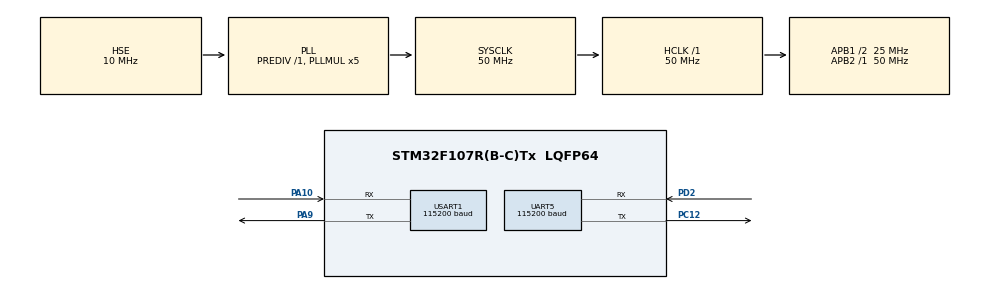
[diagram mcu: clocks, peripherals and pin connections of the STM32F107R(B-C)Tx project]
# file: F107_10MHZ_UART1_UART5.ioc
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Mcu.Family=STM32F1
Mcu.Name=STM32F107R(B-C)Tx
Mcu.Package=LQFP64
NVIC.PriorityGroup=NVIC_PRIORITYGROUP_4
NVIC.TIM1_UP_IRQn=true\:15\:0\:false\:false\:true\:false\:true\:true
NVIC.TimeBase=TIM1_UP_IRQn
NVIC.TimeBaseIP=TIM1
NVIC.UART5_IRQn=true\:0\:0\:false\:false\:true\:true\:true\:true
NVIC.USART1_IRQn=true\:0\:0\:false\:false\:true\:true\:true\:true
PA10.Mode=Asynchronous
PA10.Signal=USART1_RX
PA9.Mode=Asynchronous
PA9.Signal=USART1_TX
PC12.Mode=Asynchronous
PC12.Signal=UART5_TX
PD0-OSC_IN.Mode=HSE-External-Oscillator
PD0-OSC_IN.Signal=RCC_OSC_IN
PD1-OSC_OUT.Mode=HSE-External-Oscillator
PD1-OSC_OUT.Signal=RCC_OSC_OUT
PD2.Mode=Asynchronous
PD2.Signal=UART5_RX
ProjectManager.HeapSize=0x200
ProjectManager.StackSize=0x400
ProjectManager.TargetToolchain=STM32CubeIDE
RCC.AHBFreq_Value=50000000
RCC.APB1CLKDivider=RCC_HCLK_DIV2
RCC.APB1Freq_Value=25000000
RCC.APB1TimFreq_Value=50000000
RCC.APB2Freq_Value=50000000
RCC.APB2TimFreq_Value=50000000
RCC.HCLKFreq_Value=50000000
RCC.HSE_VALUE=10000000
RCC.PLLMUL=RCC_PLL_MUL5
RCC.PLLSourceVirtual=RCC_PLLSOURCE_HSE
RCC.SYSCLKFreq_VALUE=50000000
RCC.SYSCLKSource=RCC_SYSCLKSOURCE_PLLCLK
RCC.USBFreq_Value=33333333.333333332
UART5.BaudRate=115200
UART5.VirtualMode=Asynchronous
USART1.BaudRate=115200
USART1.VirtualMode=VM_ASYNC
VP_SYS_VS_ND.Mode=No_Debug
VP_SYS_VS_tim1.Mode=TIM1
board=custom

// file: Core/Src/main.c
/* USER CODE BEGIN Header */
/**
  ******************************************************************************
  * @file           : main.c
  * @brief          : Main program body
  ******************************************************************************
  * @attention
  *
  * Copyright (c) 2022 STMicroelectronics.
  * All rights reserved.
  *
  * This software is licensed under terms that can be found in the LICENSE file
  * in the root directory of this software component.
  * If no LICENSE file comes with this software, it is provided AS-IS.
  *
  ******************************************************************************
  */
/* USER CODE END Header */
#include "main.h"

UART_HandleTypeDef huart5;
UART_HandleTypeDef huart1;

/* USER CODE BEGIN PV */
uint8_t tmp1;
uint8_t tmp2;

/* USER CODE END PV */

void SystemClock_Config(void);
static void MX_GPIO_Init(void);
static void MX_UART5_Init(void);
static void MX_USART1_UART_Init(void);

/* USER CODE BEGIN 0 */

void HAL_UART_RxCpltCallback(UART_HandleTypeDef *huart)
{
 if(huart==&huart1)
 {
	 HAL_UART_Transmit_IT(&huart1,"uart1\n",6);
	 HAL_UART_Receive_IT(&huart1,&tmp1,1);
 }
 else if(huart==&huart5)
 {
	 HAL_UART_Transmit_IT(&huart1,"uart5\n",6);
	 HAL_UART_Receive_IT(&huart5,&tmp2,1);
 }
}

/* USER CODE END 0 */

int main(void)
{

  /* MCU Configuration--------------------------------------------------------*/

  /* Reset of all peripherals, Initializes the Flash interface and the Systick. */
  HAL_Init();

  /* Configure the system clock */
  SystemClock_Config();

  /* Initialize all configured peripherals */
  MX_GPIO_Init();
  MX_UART5_Init();
  MX_USART1_UART_Init();
  /* USER CODE BEGIN 2 */
  HAL_UART_Receive_IT(&huart1,&tmp1,1);
  HAL_UART_Receive_IT(&huart5,&tmp2,1);

  /* USER CODE END 2 */

  /* Infinite loop */
  /* USER CODE BEGIN WHILE */
  while (1)
  {
	HAL_UART_Transmit_IT(&huart1,"uart1\n",6);
	HAL_UART_Transmit_IT(&huart5,"uart5\n",6);
	HAL_Delay(2000);

    /* USER CODE END WHILE */

  }
}

void SystemClock_Config(void)
{
  RCC_OscInitTypeDef RCC_OscInitStruct = {0};
  RCC_ClkInitTypeDef RCC_ClkInitStruct = {0};

  /** Initializes the RCC Oscillators according to the specified parameters
  * in the RCC_OscInitTypeDef structure.
  */
  RCC_OscInitStruct.OscillatorType = RCC_OSCILLATORTYPE_HSE;
  RCC_OscInitStruct.HSEState = RCC_HSE_ON;
  RCC_OscInitStruct.HSEPredivValue = RCC_HSE_PREDIV_DIV1;
  RCC_OscInitStruct.HSIState = RCC_HSI_ON;
  RCC_OscInitStruct.Prediv1Source = RCC_PREDIV1_SOURCE_HSE;
  RCC_OscInitStruct.PLL.PLLState = RCC_PLL_ON;
  RCC_OscInitStruct.PLL.PLLSource = RCC_PLLSOURCE_HSE;
  RCC_OscInitStruct.PLL.PLLMUL = RCC_PLL_MUL5;
  RCC_OscInitStruct.PLL2.PLL2State = RCC_PLL_NONE;
  if (HAL_RCC_OscConfig(&RCC_OscInitStruct) != HAL_OK)
  {
    Error_Handler();
  }

  /** Initializes the CPU, AHB and APB buses clocks
  */
  RCC_ClkInitStruct.ClockType = RCC_CLOCKTYPE_HCLK|RCC_CLOCKTYPE_SYSCLK
                              |RCC_CLOCKTYPE_PCLK1|RCC_CLOCKTYPE_PCLK2;
  RCC_ClkInitStruct.SYSCLKSource = RCC_SYSCLKSOURCE_PLLCLK;
  RCC_ClkInitStruct.AHBCLKDivider = RCC_SYSCLK_DIV1;
  RCC_ClkInitStruct.APB1CLKDivider = RCC_HCLK_DIV2;
  RCC_ClkInitStruct.APB2CLKDivider = RCC_HCLK_DIV1;

  if (HAL_RCC_ClockConfig(&RCC_ClkInitStruct, FLASH_LATENCY_2) != HAL_OK)
  {
    Error_Handler();
  }

  /** Configure the Systick interrupt time
  */
  __HAL_RCC_PLLI2S_ENABLE();
}

static void MX_UART5_Init(void)
{

  huart5.Instance = UART5;
  huart5.Init.BaudRate = 115200;
  huart5.Init.WordLength = UART_WORDLENGTH_8B;
  huart5.Init.StopBits = UART_STOPBITS_1;
  huart5.Init.Parity = UART_PARITY_NONE;
  huart5.Init.Mode = UART_MODE_TX_RX;
  huart5.Init.HwFlowCtl = UART_HWCONTROL_NONE;
  huart5.Init.OverSampling = UART_OVERSAMPLING_16;
  if (HAL_UART_Init(&huart5) != HAL_OK)
  {
    Error_Handler();
  }

}

static void MX_USART1_UART_Init(void)
{

  huart1.Instance = USART1;
  huart1.Init.BaudRate = 115200;
  huart1.Init.WordLength = UART_WORDLENGTH_8B;
  huart1.Init.StopBits = UART_STOPBITS_1;
  huart1.Init.Parity = UART_PARITY_NONE;
  huart1.Init.Mode = UART_MODE_TX_RX;
  huart1.Init.HwFlowCtl = UART_HWCONTROL_NONE;
  huart1.Init.OverSampling = UART_OVERSAMPLING_16;
  if (HAL_UART_Init(&huart1) != HAL_OK)
  {
    Error_Handler();
  }

}

static void MX_GPIO_Init(void)
{

  /* GPIO Ports Clock Enable */
  __HAL_RCC_GPIOD_CLK_ENABLE();
  __HAL_RCC_GPIOA_CLK_ENABLE();
  __HAL_RCC_GPIOC_CLK_ENABLE();

}

void HAL_TIM_PeriodElapsedCallback(TIM_HandleTypeDef *htim)
{
  if (htim->Instance == TIM1) {
    HAL_IncTick();
  }
}

void Error_Handler(void)
{
  __disable_irq();
  while (1)
  {
  }
}
